# PCIE0_CORE_ECC_AGGR1 register map
Vendor: Texas Instruments
Peripheral module from a debugger description file (folder J7ES).
Registers are 32-bit, access not given, reset 0x0 unless marked. A register's access mark holds for its fields unless they carry their own. Offsets are as the file gives them; lines under a group give offsets from that group; [hi:lo] are bit positions; {n}, {i} and the like mark numbered series; 'fields as' and 'values as' point back to an identical list; <NAME> marks a mode.

## PCIE0_CORE_ECC_AGGR1
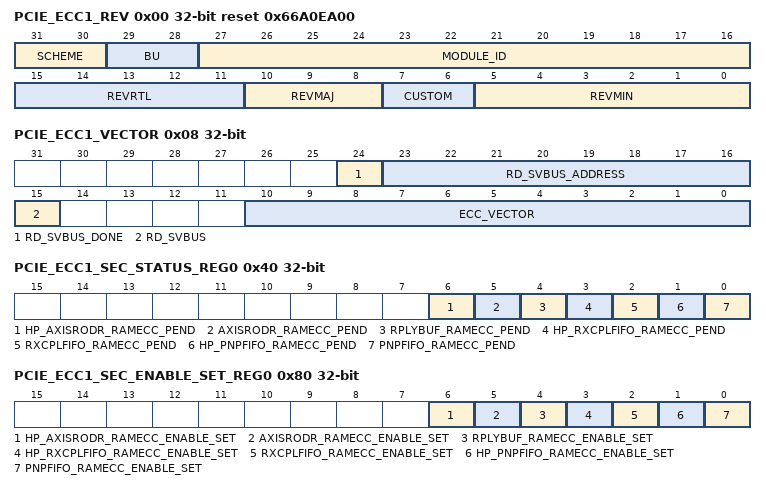
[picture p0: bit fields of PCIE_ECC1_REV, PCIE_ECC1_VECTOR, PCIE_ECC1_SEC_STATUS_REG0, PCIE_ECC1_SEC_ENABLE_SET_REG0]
0x00 PCIE_ECC1_REV ro reset 0x66A0EA00 — Revision parameters
  [31:30] SCHEME
  [29:28] BU
  [27:16] MODULE_ID
  [15:11] REVRTL — RTL version
  [10:8] REVMAJ — Major version
  [7:6] CUSTOM — Custom version
  [5:0] REVMIN — Minor version
0x08 PCIE_ECC1_VECTOR — ECC Register
  [24] RD_SVBUS_DONE — Status to indicate if read on serial VBUS is complete, write of any value will clear this bit. (access RW1C)
  [23:16] RD_SVBUS_ADDRESS rw — Read address
  [15] RD_SVBUS — Write 1 to trigger a read on the serial VBUS (access RW1S)
  [10:0] ECC_VECTOR rw — Value written to select the corresponding ECC RAM for control or status
0x0C PCIE_ECC1_STAT ro reset 0x7 — Misc Status
  [10:0] NUM_RAMS — Indicates the number of RAMS serviced by the ECC aggregator
0x10 PCIE_ECC1_RESERVED_SVBUS_y rw — Reference other documents that contain the ECC RAM wrapper and EDC controller serial vbus register sets. Offset = 10h + (y * 4h); where y = 0h to 7h
  [31:0] DATA — Serial VBUS register data
0x3C PCIE_ECC1_SEC_EOI_REG — EOI Register
  [0] EOI_WR — EOI Register (access RW1S)
0x40 PCIE_ECC1_SEC_STATUS_REG0 — Interrupt Status Register 0
  [6] HP_AXISRODR_RAMECC_PEND — Interrupt Pending Status for hp_axisrodr_ramecc_pend (access RW1S)
  [5] AXISRODR_RAMECC_PEND — Interrupt Pending Status for axisrodr_ramecc_pend (access RW1S)
  [4] RPLYBUF_RAMECC_PEND — Interrupt Pending Status for rplybuf_ramecc_pend (access RW1S)
  [3] HP_RXCPLFIFO_RAMECC_PEND — Interrupt Pending Status for hp_rxcplfifo_ramecc_pend (access RW1S)
  [2] RXCPLFIFO_RAMECC_PEND — Interrupt Pending Status for rxcplfifo_ramecc_pend (access RW1S)
  [1] HP_PNPFIFO_RAMECC_PEND — Interrupt Pending Status for hp_pnpfifo_ramecc_pend (access RW1S)
  [0] PNPFIFO_RAMECC_PEND — Interrupt Pending Status for pnpfifo_ramecc_pend (access RW1S)
0x80 PCIE_ECC1_SEC_ENABLE_SET_REG0 — Interrupt Enable Set Register 0
  [6] HP_AXISRODR_RAMECC_ENABLE_SET — Interrupt Enable Set Register for hp_axisrodr_ramecc_pend (access RW1S)
  [5] AXISRODR_RAMECC_ENABLE_SET — Interrupt Enable Set Register for axisrodr_ramecc_pend (access RW1S)
  [4] RPLYBUF_RAMECC_ENABLE_SET — Interrupt Enable Set Register for rplybuf_ramecc_pend (access RW1S)
  [3] HP_RXCPLFIFO_RAMECC_ENABLE_SET — Interrupt Enable Set Register for hp_rxcplfifo_ramecc_pend (access RW1S)
  [2] RXCPLFIFO_RAMECC_ENABLE_SET — Interrupt Enable Set Register for rxcplfifo_ramecc_pend (access RW1S)
  [1] HP_PNPFIFO_RAMECC_ENABLE_SET — Interrupt Enable Set Register for hp_pnpfifo_ramecc_pend (access RW1S)
  [0] PNPFIFO_RAMECC_ENABLE_SET — Interrupt Enable Set Register for pnpfifo_ramecc_pend (access RW1S)
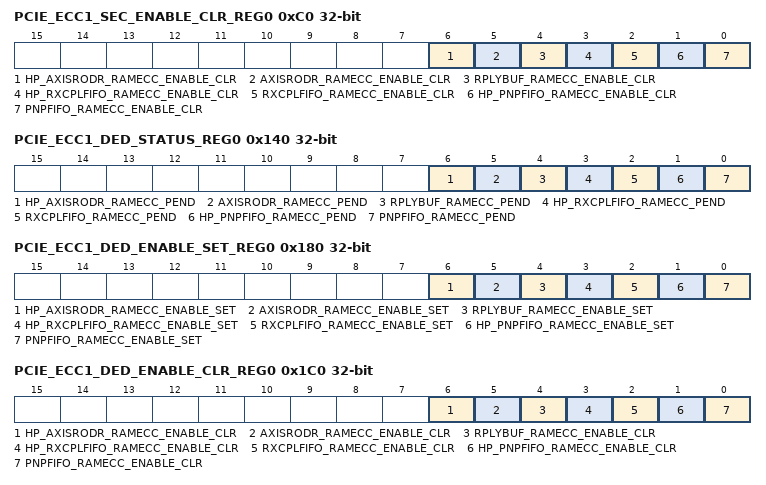
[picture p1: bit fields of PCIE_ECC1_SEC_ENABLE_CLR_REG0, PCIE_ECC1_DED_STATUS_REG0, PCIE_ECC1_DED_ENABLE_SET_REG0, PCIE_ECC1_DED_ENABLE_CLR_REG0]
0xC0 PCIE_ECC1_SEC_ENABLE_CLR_REG0 — Interrupt Enable Clear Register 0
  [6] HP_AXISRODR_RAMECC_ENABLE_CLR — Interrupt Enable Clear Register for hp_axisrodr_ramecc_pend (access RW1C)
  [5] AXISRODR_RAMECC_ENABLE_CLR — Interrupt Enable Clear Register for axisrodr_ramecc_pend (access RW1C)
  [4] RPLYBUF_RAMECC_ENABLE_CLR — Interrupt Enable Clear Register for rplybuf_ramecc_pend (access RW1C)
  [3] HP_RXCPLFIFO_RAMECC_ENABLE_CLR — Interrupt Enable Clear Register for hp_rxcplfifo_ramecc_pend (access RW1C)
  [2] RXCPLFIFO_RAMECC_ENABLE_CLR — Interrupt Enable Clear Register for rxcplfifo_ramecc_pend (access RW1C)
  [1] HP_PNPFIFO_RAMECC_ENABLE_CLR — Interrupt Enable Clear Register for hp_pnpfifo_ramecc_pend (access RW1C)
  [0] PNPFIFO_RAMECC_ENABLE_CLR — Interrupt Enable Clear Register for pnpfifo_ramecc_pend (access RW1C)
0x13C PCIE_ECC1_DED_EOI_REG — EOI Register
  [0] EOI_WR — EOI Register (access RW1S)
0x140 PCIE_ECC1_DED_STATUS_REG0 — Interrupt Status Register 0
  fields as PCIE_ECC1_SEC_STATUS_REG0
0x180 PCIE_ECC1_DED_ENABLE_SET_REG0 — Interrupt Enable Set Register 0
  fields as PCIE_ECC1_SEC_ENABLE_SET_REG0
0x1C0 PCIE_ECC1_DED_ENABLE_CLR_REG0 — Interrupt Enable Clear Register 0
  fields as PCIE_ECC1_SEC_ENABLE_CLR_REG0
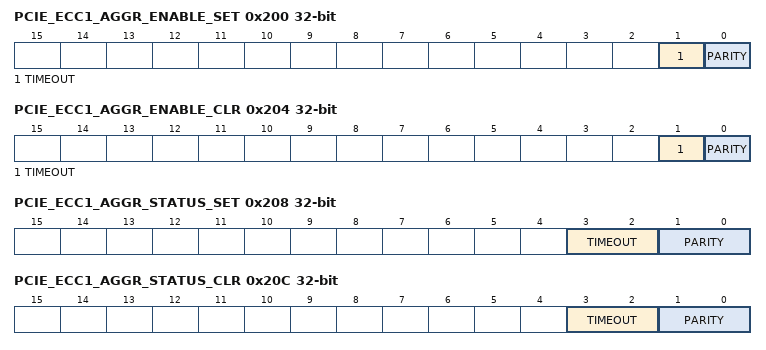
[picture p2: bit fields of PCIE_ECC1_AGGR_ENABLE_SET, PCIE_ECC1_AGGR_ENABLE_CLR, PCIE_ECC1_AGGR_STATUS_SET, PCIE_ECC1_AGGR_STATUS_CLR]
0x200 PCIE_ECC1_AGGR_ENABLE_SET — AGGR interrupt enable set Register
  [1] TIMEOUT — interrupt enable set for svbus timeout errors (access RW1S)
  [0] PARITY — interrupt enable set for parity errors (access RW1S)
0x204 PCIE_ECC1_AGGR_ENABLE_CLR — AGGR interrupt enable clear Register
  [1] TIMEOUT — interrupt enable clear for svbus timeout errors (access RW1C)
  [0] PARITY — interrupt enable clear for parity errors (access RW1C)
0x208 PCIE_ECC1_AGGR_STATUS_SET — AGGR interrupt status set Register
  [3:2] TIMEOUT — interrupt status set for svbus timeout errors (access RWincr)
  [1:0] PARITY — interrupt status set for parity errors (access RWincr)
0x20C PCIE_ECC1_AGGR_STATUS_CLR — AGGR interrupt status clear Register
  [3:2] TIMEOUT — interrupt status clear for svbus timeout errors (access RWdecr)
  [1:0] PARITY — interrupt status clear for parity errors (access RWdecr)
